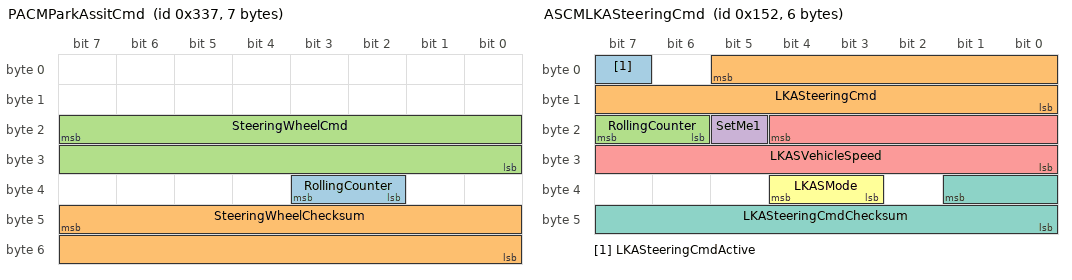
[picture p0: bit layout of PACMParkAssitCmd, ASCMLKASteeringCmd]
BO_ 823 PACMParkAssitCmd: 7 NEO
 SG_ RollingCounter : 35|2@0+ (1,0) [0|0] ""  NEO
 SG_ SteeringWheelChecksum : 47|16@0+ (1,0) [0|0] ""  NEO
 SG_ SteeringWheelCmd : 23|16@0+ (1,0) [0|0] ""  NEO

BO_ 560 EBCMRegen: 6 K17_EBCM
 SG_ Regen : 1|10@0+ (1,0) [0|0] ""  NEO

BO_ 338 ASCMLKASteeringCmd: 6 NEO
 SG_ LKASteeringCmdActive : 7|1@0+ (1,0) [0|0] ""  NEO
 SG_ LKASteeringCmd : 5|14@0- (1,0) [0|0] ""  NEO
 SG_ RollingCounter : 23|2@0+ (1,0) [0|0] ""  NEO
 SG_ SetMe1 : 21|1@0+ (1,0) [0|0] ""  NEO
 SG_ LKASVehicleSpeed : 20|13@0+ (0.22,0) [0|0] "kph" NEO
 SG_ LKASMode : 36|2@0+ (1,0) [0|0] ""  NEO
 SG_ LKASteeringCmdChecksum : 33|10@0+ (1,0) [0|0] ""  NEO

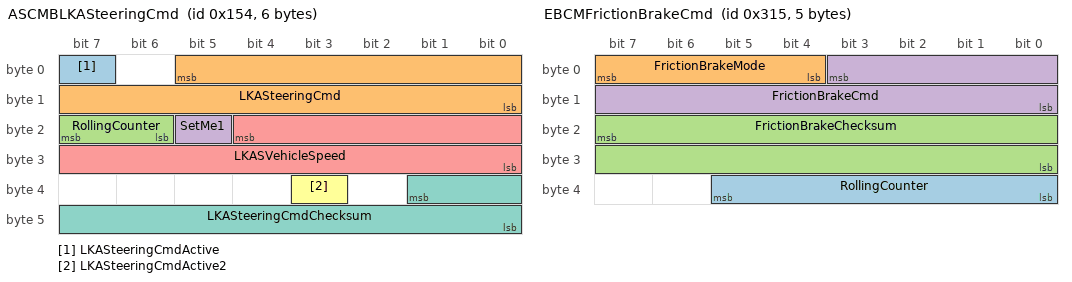
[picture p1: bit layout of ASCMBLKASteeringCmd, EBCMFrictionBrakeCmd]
BO_ 340 ASCMBLKASteeringCmd: 6 NEO
 SG_ LKASteeringCmdActive : 7|1@0+ (1,0) [0|0] ""  NEO
 SG_ LKASteeringCmd : 5|14@0- (1,0) [0|0] ""  NEO
 SG_ RollingCounter : 23|2@0+ (1,0) [0|0] ""  NEO
 SG_ SetMe1 : 21|1@0+ (1,0) [0|0] ""  NEO
 SG_ LKASVehicleSpeed : 20|13@0+ (0.22,0) [0|0] "kph" NEO
 SG_ LKASteeringCmdActive2 : 35|1@0+ (1,0) [0|0] ""  NEO
 SG_ LKASteeringCmdChecksum : 33|10@0+ (1,0) [0|0] ""  NEO

BO_ 368 EBCMFrictionBrakeStatus: 8 K17_EBCM
 SG_ FrictionBrakePressure : 23|16@0+ (1,0) [0|0] ""  NEO

BO_ 789 EBCMFrictionBrakeCmd: 5 K17_EBCM
 SG_ RollingCounter : 37|6@0+ (1,0) [0|0] ""  NEO
 SG_ FrictionBrakeMode : 7|4@0+ (1,0) [0|0] ""  NEO
 SG_ FrictionBrakeChecksum : 23|16@0+ (1,0) [0|0] ""  NEO
 SG_ FrictionBrakeCmd : 3|12@0- (1,0) [0|0] ""  NEO

BO_TX_BU_ 823 : K43_PSCM,NEO;
BO_TX_BU_ 789 : NEO,K17_EBCM;

BU_: XXX DSU HCU EPS IPAS CGW BGM

CM_ "AUTOGENERATED FILE, DO NOT EDIT";

CM_ "Imported file _comma.dbc starts here";
CM_ "Imported file _honda_common.dbc starts here";
CM_ SG_ 304 "Seems to be platform-agnostic";
CM_ SG_ 316 "Should exist on Nidec";
CM_ SG_ 420 BRAKE_HOLD_RELATED "On when Brake Hold engaged";
CM_ SG_ 490 LONG_ACCEL "wheel speed derivative, noisy and zero snapping";
CM_ SG_ 773 PASS_AIRBAG_ON "Might just be indicator light";
CM_ SG_ 773 PASS_AIRBAG_OFF "Might just be indicator light";
CM_ SG_ 780 CRUISE_SPEED "255 = no speed";
CM_ SG_ 780 PCM_SPEED "Used by Nidec";
CM_ SG_ 780 PCM_GAS "Used by Nidec";
CM_ SG_ 804 CRUISE_SPEED_PCM "255 = no speed";

CM_ "Imported file _nidec_common.dbc starts here";
CM_ SG_ 506 AEB_REQ_1 "set for duration of suspected AEB event";
CM_ SG_ 506 COMPUTER_BRAKE_ALT "Used by dual-can Nidec";
CM_ SG_ 506 BRAKE_PUMP_REQUEST_ALT "Used by dual-can Nidec";
CM_ SG_ 829 BEEP "beeps are pleasant, chimes are for warnngs etc...";

CM_ "honda_fit_hybrid_2018_can.dbc starts here";

CM_ SG_ 419 GEAR "10 = reverse, 11 = transition";
